# main_sec_mmr_MAIN_SEC_MMR_CFG0_45A00000h register map
Vendor: Texas Instruments
Peripheral module from a debugger description file (folder am62D).
Registers are 32-bit, read-write, reset 0x0 unless marked. A register's access mark holds for its fields unless they carry their own. Offsets are as the file gives them; lines under a group give offsets from that group; [hi:lo] are bit positions; {n}, {i} and the like mark numbered series; 'fields as' and 'values as' point back to an identical list; <NAME> marks a mode.

## main_sec_mmr_CFG0
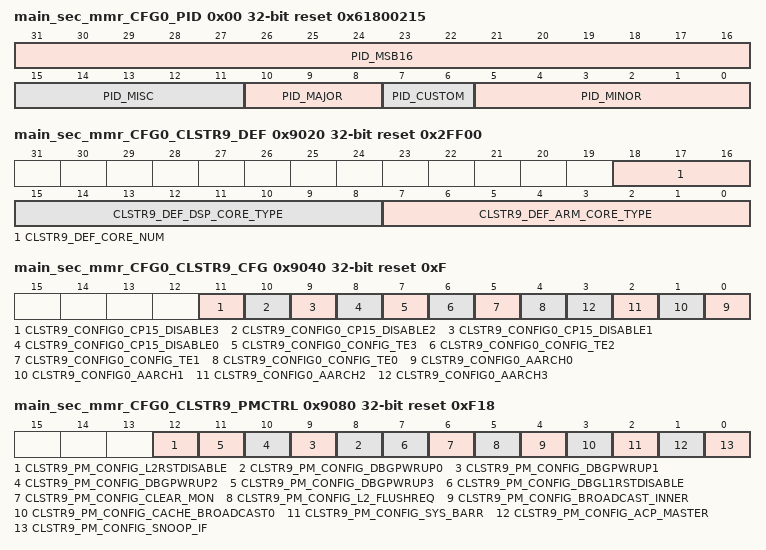
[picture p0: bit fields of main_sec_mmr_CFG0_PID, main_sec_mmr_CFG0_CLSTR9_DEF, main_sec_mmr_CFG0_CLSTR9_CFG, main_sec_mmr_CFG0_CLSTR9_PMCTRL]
0x00 main_sec_mmr_CFG0_PID ro reset 0x61800215
  [31:16] PID_MSB16 — Reset Source: mod_g_rst_n
  [15:11] PID_MISC — Reset Source: mod_g_rst_n
  [10:8] PID_MAJOR — Reset Source: mod_g_rst_n
  [7:6] PID_CUSTOM — Reset Source: mod_g_rst_n
  [5:0] PID_MINOR — Reset Source: mod_g_rst_n
0x9020 main_sec_mmr_CFG0_CLSTR9_DEF ro reset 0x2FF00
  [18:16] CLSTR9_DEF_CORE_NUM — Number of cores in cluster 000 - Single Core 001 - Dual Core 010 - Quad Core Reset Source: mod_g_rst_n
  [15:8] CLSTR9_DEF_DSP_CORE_TYPE — DSP core type configurationField values (others are reserved):8'h00 - C7x8'h01 - C6x8'h10 - AC7x8'hFF - Not DSP Reset Source: mod_g_rst_n
  [7:0] CLSTR9_DEF_ARM_CORE_TYPE — ARM core type configurationField values (others are reserved):8'h00 - A538'h01 - A578'h10 - R58'h11 - M4F8'hFF - Not ARM Reset Source: mod_g_rst_n
0x9040 main_sec_mmr_CFG0_CLSTR9_CFG reset 0xF
  [11] CLSTR9_CONFIG0_CP15_DISABLE3 — Deactivate write access to secure CP15 registers for Core3 0 - Access activated1 - Access deactivatedCAUTION: This bit must not be modified while A53 CPU is released from reset. Reset Source: mod_g_rst_n
  [10] CLSTR9_CONFIG0_CP15_DISABLE2 — Deactivate write access to secure CP15 registers for Core2 0 - Access activated1 - Access deactivatedCAUTION: This bit must not be modified while A53 CPU is released from reset. Reset Source: mod_g_rst_n
  [9] CLSTR9_CONFIG0_CP15_DISABLE1 — Deactivate write access to secure CP15 registers for Core10 - Access activated1 - Access deactivatedCAUTION: This bit must not be modified while A53 CPU is released from reset. Reset Source: mod_g_rst_n
  [8] CLSTR9_CONFIG0_CP15_DISABLE0 — Deactivate write access to secure CP15 registers for Core00 - Access activated1 - Access deactivatedCAUTION: This bit must not be modified while A53 CPU is released from reset. Reset Source: mod_g_rst_n
  [7] CLSTR9_CONFIG0_CONFIG_TE3 — Activate T32 exceptions for Core3 Sets the initial value of the TE bit in the CP15 SCTLR register. This bitfield is sampled only during reset of the processor.0 - TE bit is LOW1 - TE bit is HIGHCAUTION: This bit must not be modified while A53 CPU is released from reset. Reset Source: mod_g_rst_n
  [6] CLSTR9_CONFIG0_CONFIG_TE2 — Activate T32 exceptions for Core2 Sets the initial value of the TE bit in the CP15 SCTLR register. This bitfield is sampled only during reset of the processor.0 - TE bit is LOW1 - TE bit is HIGHCAUTION: This bit must not be modified while A53 CPU is released from reset. Reset Source: mod_g_rst_n
  [5] CLSTR9_CONFIG0_CONFIG_TE1 — Activate T32 exceptions for Core1Sets the initial value of the TE bit in the CP15 SCTLR register. This bitfield is sampled only during reset of the processor.0 - TE bit is LOW1 - TE bit is HIGH CAUTION: This bit must not be modified while A53 CPU is released from reset. Reset Source: mod_g_rst_n
  [4] CLSTR9_CONFIG0_CONFIG_TE0 — Activate T32 exceptions for Core0Sets the initial value of the TE bit in the CP15 SCTLR register. This bitfield is sampled only during reset of the processor.0 - TE bit is LOW1 - TE bit is HIGH CAUTION: This bit must not be modified while A53 CPU is released from reset. Reset Source: mod_g_rst_n
  [n] CLSTR9_CONFIG0_AARCH{n} (n=0..3) — Core{n} ARM Architecture configuration0 - AArch321 - AArch64 CAUTION: This bit must not be modified while A53 CPU is released from reset. Reset Source: mod_g_rst_n
0x9080 main_sec_mmr_CFG0_CLSTR9_PMCTRL reset 0xF18
  [12] CLSTR9_PM_CONFIG_L2RSTDISABLE — Deactivate L2 cache automatic invalidate on reset functionality.This pin is sampled only during reset of the processor.0 - Activate automatic invalidation of L2 cache on reset.1 - Deactivate automatic invalidation of L2 cache on reset. Reset Source: mod_g_rst_n
  [n+8] CLSTR9_PM_CONFIG_DBGPWRUP{n} (n=0..3) — Core{n} powered up0 - Core is powered down1 - Core is powered up Reset Source: mod_g_rst_n
  [7] CLSTR9_PM_CONFIG_DBGL1RSTDISABLE — Deactivate L1 data cache automatic invalidate on reset functionality.This pin is sampled only during reset of the processor.0 - Activate automatic invalidation of L1 data cache on reset.1 - Deactivate automatic invalidation of L1 data cache on reset. Reset Source: mod_g_rst_n
  [6] CLSTR9_PM_CONFIG_CLEAR_MON — Request to clear the external global exclusive monitor.This sends a WFE wake-up event to all cores in the cluster. When set HIGH the global exclusive monitor in the system is requesting the processor EVENT registers to be set HIGH. Reset Source: mod_g_rst_n
  [5] CLSTR9_PM_CONFIG_L2_FLUSHREQ — ARM L2 hardware flush request Reset Source: mod_g_rst_n
  [4] CLSTR9_PM_CONFIG_BROADCAST_INNER — Activate broadcasting of inner and outer shareable transactions0 - Deactivated1 - Activated Reset Source: mod_g_rst_n
  [3] CLSTR9_PM_CONFIG_CACHE_BROADCAST0 — Activate broadcasting of cache maintenance transactions:0 - DIsable1 - Activate Reset Source: mod_g_rst_n
  [2] CLSTR9_PM_CONFIG_SYS_BARR — Deactivate broadcasting of barriers:0 - Activate1 - Deactivate Reset Source: mod_g_rst_n
  [1] CLSTR9_PM_CONFIG_ACP_MASTER — ACP controller is inactive and is not participating in coherency. There mustbe no outstanding transactions when the controller asserts this signal, and while it is asserted the controller must not send any new transactions:0 - ACP controller is active1 - ACP controller is inactive Reset Source: mod_g_rst_n
  [0] CLSTR9_PM_CONFIG_SNOOP_IF — Snoop interface is inactive and not participating in coherency:0 - Snoop interface is active.1 - Snoop interface is inactive. Reserved/Unconnected on AM64x (No MSMC) Reset Source: mod_g_rst_n
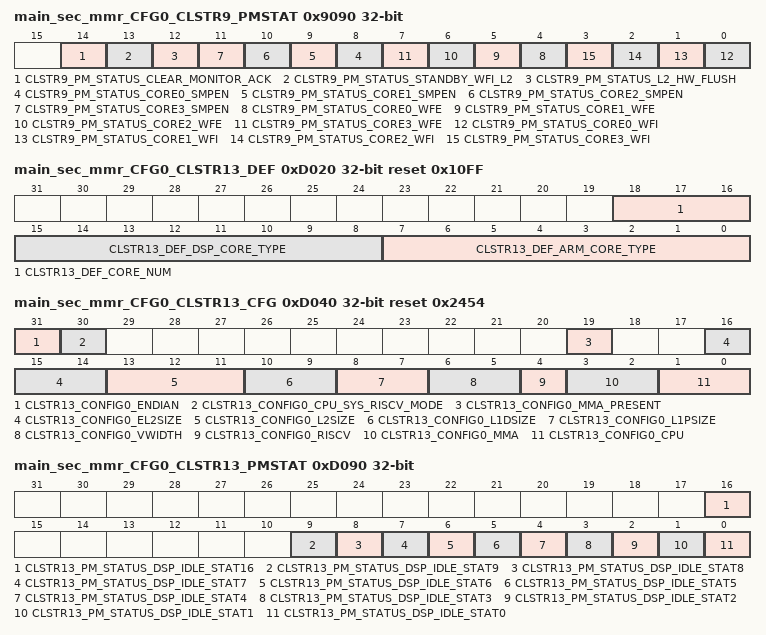
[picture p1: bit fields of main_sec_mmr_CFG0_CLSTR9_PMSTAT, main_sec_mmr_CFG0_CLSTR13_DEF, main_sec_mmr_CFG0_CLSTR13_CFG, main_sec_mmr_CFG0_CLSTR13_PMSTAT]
0x9090 main_sec_mmr_CFG0_CLSTR9_PMSTAT ro
  [14] CLSTR9_PM_STATUS_CLEAR_MONITOR_ACK — External global exclusive monitor clear acknowledge.Set HIGH to acknowledge the receipt of the CLREXMONREQ input (PM_CONFIG0_clear_mon0 is set). Indicates that the processor EVENT registers have been set HIGH. Reset Source: mod_g_rst_n
  [13] CLSTR9_PM_STATUS_STANDBY_WFI_L2 — Indicates L2 low power state0 - L2 not in low power state1 - L2 is in WFI low power state Reset Source: mod_g_rst_n
  [12] CLSTR9_PM_STATUS_L2_HW_FLUSH — L2 hardware flush complete Reset Source: mod_g_rst_n
  [n+8] CLSTR9_PM_STATUS_CORE{n}_SMPEN (n=0..3) — Core{n} coherency indicator0 - Core is taking part in coherency1 - Core is not taking part in coherency Reset Source: mod_g_rst_n
  [n+4] CLSTR9_PM_STATUS_CORE{n}_WFE (n=0..3) — Indicates Core{n} in WFE stateNote: Informaton is only valid when core is out of reset. Reset Source: mod_g_rst_n
  [n] CLSTR9_PM_STATUS_CORE{n}_WFI (n=0..3) — Indicates Core{n} in WFI stateNote: Informaton is only valid when core is out of reset. Reset Source: mod_g_rst_n
{0x9110+0x80*i} main_sec_mmr_CFG0_CLSTR9_CORE{i}_BOOTVECT_LO (i=0..3)
  [31:0] CLSTR9_RST_VEC_LO_CORE{i}_RESET_BASE_VECTOR_LO — Core{i} - Reset base vector (v8 Mode) Address[33:2]CAUTION: This bit must not be modified while A53 CPU is released from reset. Reset Source: mod_g_rst_n
{0x9114+0x80*i} main_sec_mmr_CFG0_CLSTR9_CORE{i}_BOOTVECT_HI (i=0..3)
  [1:0] CLSTR9_RST_VEC_HI_CORE{i}_RESET_BASE_VECTOR_HI — Core{i} - Reset base vector (v8 Mode) Address[35:34]CAUTION: This bit must not be modified while A53 CPU is released from reset. Reset Source: mod_g_rst_n
0xD020 main_sec_mmr_CFG0_CLSTR13_DEF ro reset 0x10FF
  [18:16] CLSTR13_DEF_CORE_NUM — Number of cores in cluster 000 - Single Core 001 - Dual Core 010 - Quad Core Reset Source: mod_g_rst_n
  [15:8] CLSTR13_DEF_DSP_CORE_TYPE — DSP core type configurationField values (others are reserved):8'h00 - C7x8'h01 - C6x8'h10 - AC7x8'hFF - Not DSP Reset Source: mod_g_rst_n
  [7:0] CLSTR13_DEF_ARM_CORE_TYPE — ARM core type configurationField values (others are reserved):8'h00 - A538'h01 - A578'h10 - R58'h11 - M4F8'hFF - Not ARM Reset Source: mod_g_rst_n
0xD040 main_sec_mmr_CFG0_CLSTR13_CFG access per field reset 0x2454
  [31] CLSTR13_CONFIG0_ENDIAN rw — Reset value of Endian control. Valid for DSP only.0 - Little Endian1 - Big Endian Reset Source: mod_g_rst_n
  [30] CLSTR13_CONFIG0_CPU_SYS_RISCV_MODE rw — Activates CPU Booting in RiscV Mode0 - Boot in C7x ISA Mode1 - Boot in RiscV ISA Mode Reset Source: mod_g_rst_n
  [19] CLSTR13_CONFIG0_MMA_PRESENT rw — MMA Present Based on EFUSE. This bit is intended to be read not modified and writes to this bit will not have any impact on the C7xv256 mma present which is directly controlled by efuse. Reset Source: mod_g_rst_n
  [16:14] CLSTR13_CONFIG0_EL2SIZE ro — EL2 SizeField values (others are reserved):3'b111 - 4MB3'b110 - 3.5MB3'b101 - 3MB3'b100 - 2.5MB3'b011 - 2MB3'b010 - 1.5MB3'b001 - 1MB3'b000 - None Reset Source: mod_g_rst_n
  [13:11] CLSTR13_CONFIG0_L2SIZE ro — L2 SizeField values (others are reserved):3'b111 - 2MB3'b110 - 1.75MB3'b101 - 1.5MB3'b100 - 1.25MB3'b011 - 1.0MB3'b010 - 768KB3'b001 - 512KB3'b000 - None Reset Source: mod_g_rst_n
  [10:9] CLSTR13_CONFIG0_L1DSIZE ro — L1D SizeField values (others are reserved):2'b11 - 128KB2'b10 - 64KB2'b01 - 48KB2'b00 - 32KB Reset Source: mod_g_rst_n
  [8:7] CLSTR13_CONFIG0_L1PSIZE ro — L1P SizeField values (others are reserved):2'b11 - 128KB2'b10 - 64KB2'b01 - 48KB2'b00 - 32KB Reset Source: mod_g_rst_n
  [6:5] CLSTR13_CONFIG0_VWIDTH ro — Vector WidthField values (others are reserved):2'b11 - 512b2'b10 - 256b2'b01 - 128b2'b00 - 64b Reset Source: mod_g_rst_n
  [4] CLSTR13_CONFIG0_RISCV ro — RISCV ISA SUPPORTField values (others are reserved):1'b1 - Supported1'b0 - Not Supported Reset Source: mod_g_rst_n
  [3:2] CLSTR13_CONFIG0_MMA ro — MMA TypeField values (others are reserved):2'b11 - MMA22'b10 - MMA2P12'b01 - Reserved2'b00 - Reserved Reset Source: mod_g_rst_n
  [1:0] CLSTR13_CONFIG0_CPU ro — CPU TypeField values (others are reserved):2'b11 - Reserved2'b10 - Reserved2'b01 - Reserved2'b00 - AC72 R10 Reset Source: mod_g_rst_n
0xD090 main_sec_mmr_CFG0_CLSTR13_PMSTAT ro
  [16] CLSTR13_PM_STATUS_DSP_IDLE_STAT16 — C7x PBIST Idle StatusField values (others are reserved):1'b1 - Idle1'b0 - Not Idle Reset Source: mod_g_rst_n
  [9] CLSTR13_PM_STATUS_DSP_IDLE_STAT9 — ReservedField values (others are reserved):1'b1 - Idle1'b0 - Not Idle Reset Source: mod_g_rst_n
  [8] CLSTR13_PM_STATUS_DSP_IDLE_STAT8 — C7x DRU Idle StatusField values (others are reserved):1'b1 - Idle1'b0 - Not Idle Reset Source: mod_g_rst_n
  [7] CLSTR13_PM_STATUS_DSP_IDLE_STAT7 — C7x L2 Idle StatusField values (others are reserved):1'b1 - Idle1'b0 - Not Idle Reset Source: mod_g_rst_n
  [6] CLSTR13_PM_STATUS_DSP_IDLE_STAT6 — C7x Debug Idle StatusField values (others are reserved):1'b1 - Idle1'b0 - Not Idle Reset Source: mod_g_rst_n
  [5] CLSTR13_PM_STATUS_DSP_IDLE_STAT5 — C7x SE Idle StatusField values (others are reserved):1'b1 - Idle1'b0 - Not Idle Reset Source: mod_g_rst_n
  [4] CLSTR13_PM_STATUS_DSP_IDLE_STAT4 — C7x DMC Idle StatusField values (others are reserved):1'b1 - Idle1'b0 - Not Idle Reset Source: mod_g_rst_n
  [3] CLSTR13_PM_STATUS_DSP_IDLE_STAT3 — C7x PMC Idle StatusField values (others are reserved):1'b1 - Idle1'b0 - Not Idle Reset Source: mod_g_rst_n
  [2] CLSTR13_PM_STATUS_DSP_IDLE_STAT2 — C7x CPU Idle StatusField values (others are reserved):1'b1 - Idle1'b0 - Not Idle Reset Source: mod_g_rst_n
  [1] CLSTR13_PM_STATUS_DSP_IDLE_STAT1 — C7x Core LPSC Idle StatusField values (others are reserved):1'b1 - Idle1'b0 - Not Idle Reset Source: mod_g_rst_n
  [0] CLSTR13_PM_STATUS_DSP_IDLE_STAT0 — Composite Idle StatusField values (others are reserved):1'b1 - Idle1'b0 - Not Idle Reset Source: mod_g_rst_n
0xD110 main_sec_mmr_CFG0_CLSTR13_CORE0_BOOTVECT_LO
  [31:0] CLSTR13_RST_VEC_LO_CORE0_RESET_BASE_VECTOR_LO — Reset Vector Base Address 33:2 for C7x DSP Reset Source: mod_g_rst_n
0xD114 main_sec_mmr_CFG0_CLSTR13_CORE0_BOOTVECT_HI
  [1:0] CLSTR13_RST_VEC_HI_CORE0_RESET_BASE_VECTOR_HI — Reset Vector Base Address 35:34 for C7x DSP Reset Source: mod_g_rst_n
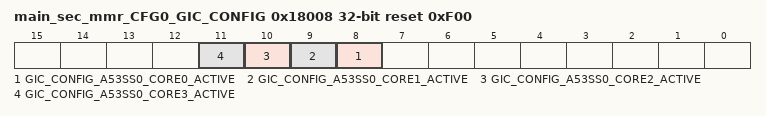
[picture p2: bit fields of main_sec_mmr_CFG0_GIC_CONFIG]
0x18008 main_sec_mmr_CFG0_GIC_CONFIG reset 0xF00
  [n+8] GIC_CONFIG_A53SS0_CORE{n}_ACTIVE (n=0..3) — Drives GIC cpu_active input for A53SS0 Core{n}.When a core is in a low-power mode (cpu_active=0), the GIC will not route shared-SPI events to the core which would wake up the core resulting in increased power consumption.0 - Core is in a software-transparent low power mode1 - Core is active and available for shared SPIs Reset Source: mod_g_rst_n
